# WS53 register map
File version: 0.1.0-experimental
Registers are 32-bit, read-write, no defined reset value unless marked. A register's access mark holds for its fields unless they carry their own. Offsets are from the block's base; [hi:lo] are bit positions; {n}, {i} and the like mark numbered series; 'fields as' and 'values as' point back to an identical list.

## SPI0
Base 0x52087000
0x00 ENABLE
  [0] START
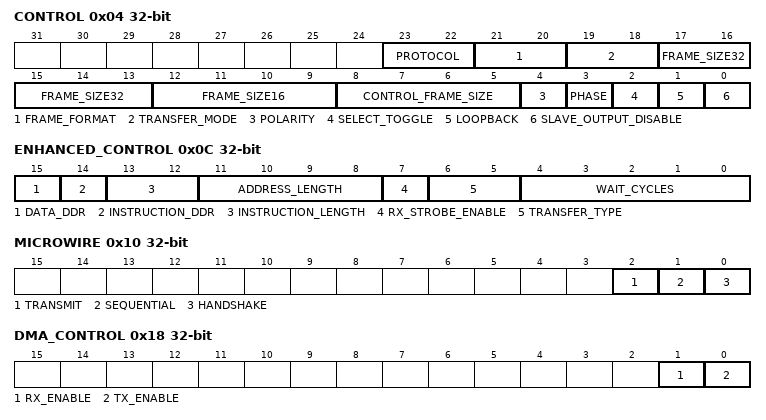
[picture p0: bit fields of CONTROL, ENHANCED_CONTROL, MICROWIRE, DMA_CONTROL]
0x04 CONTROL
  [23:22] PROTOCOL, [21:20] FRAME_FORMAT, [19:18] TRANSFER_MODE, [17:13] FRAME_SIZE32, [12:9] FRAME_SIZE16, [8:5] CONTROL_FRAME_SIZE, [4] POLARITY, [3] PHASE, [2] SELECT_TOGGLE, [1] LOOPBACK, [0] SLAVE_OUTPUT_DISABLE
0x08 FRAME_COUNT
  [15:0] VALUE
0x0C ENHANCED_CONTROL
  [15] DATA_DDR, [14] INSTRUCTION_DDR, [13:12] INSTRUCTION_LENGTH, [11:8] ADDRESS_LENGTH, [7] RX_STROBE_ENABLE, [6:5] TRANSFER_TYPE, [4:0] WAIT_CYCLES
0x10 MICROWIRE
  [2] TRANSMIT, [1] SEQUENTIAL, [0] HANDSHAKE
0x14 BAUD
  [15:0] VALUE — SDK header: even divider 2..65534, bit0 fixed zero; zero disables SCK. Setter truncates to 16 bits and does not round; silicon behavior unverified
0x18 DMA_CONTROL
  [1] RX_ENABLE, [0] TX_ENABLE
0x1C DMA_RX_LEVEL
  [31:0] VALUE
0x20 DMA_TX_LEVEL
  [31:0] VALUE
0x24 RX_SAMPLE_DELAY
  [7:0] VALUE
0x28 TX_DRIVE_EDGE
  [7:0] VALUE
{0x2C+4i} RX[{i}] (i=0..35) ro read-has-side-effects
  [31:0] DATA read-has-side-effects — Pop one received frame from the shared RX FIFO, regardless of window index
{0x2C+4i} TX[{i}] (i=0..35) wo (alternate view of RX[{i}])
  [31:0] DATA — Push one frame into the shared TX FIFO, regardless of window index
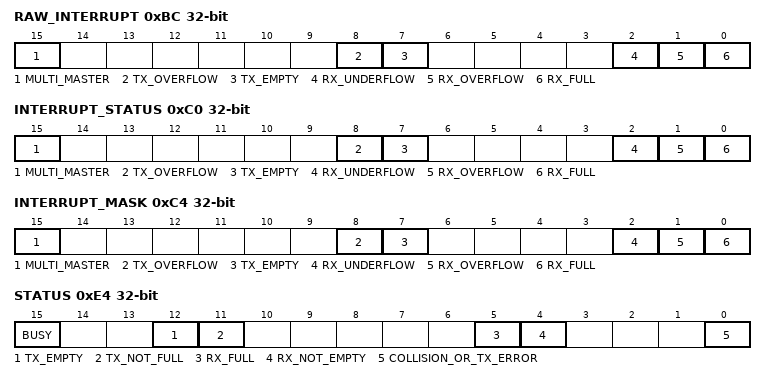
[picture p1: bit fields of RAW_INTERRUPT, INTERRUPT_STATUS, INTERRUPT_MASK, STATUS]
0xBC RAW_INTERRUPT ro
  [15] MULTI_MASTER, [8] TX_OVERFLOW, [7] TX_EMPTY, [2] RX_UNDERFLOW, [1] RX_OVERFLOW, [0] RX_FULL
0xC0 INTERRUPT_STATUS ro
  fields as RAW_INTERRUPT
0xC4 INTERRUPT_MASK
  fields as RAW_INTERRUPT
0xC8 SLAVE_ENABLE
  [15:0] VALUE
0xCC TX_THRESHOLD
  [31:0] VALUE
0xD0 TX_LEVEL ro
  [31:0] VALUE
0xD4 CLEAR_TX_OVERFLOW ro read-clears
  [0] CLEAR read-clears — Read acknowledges the corresponding interrupt; writes have no effect
0xD8 RX_THRESHOLD
  [31:0] VALUE
0xDC RX_LEVEL ro
  [31:0] VALUE
0xE0 CLEAR_RX_UNDERFLOW ro read-clears
  fields as CLEAR_TX_OVERFLOW
0xE4 STATUS ro read-modifies
  [15] BUSY
  [12] TX_EMPTY
  [11] TX_NOT_FULL
  [5] RX_FULL
  [4] RX_NOT_EMPTY
  [0] COLLISION_OR_TX_ERROR read-clears — SDK spi_wsr_data_t: master collision status clears on read. Retain the existing field name for API compatibility; the SDK documentation establishes master collision, not TX FIFO overflow. Relation to RAW_INTERRUPT acknowledgement is not established; do not use STATUS as an IRQ acknowledgement. SDK documentation, not silicon-qualified.
0xE8 CLEAR_MULTI_MASTER ro read-clears
  fields as CLEAR_TX_OVERFLOW
0xEC VERSION ro
  [31:0] VALUE
0xF4 CLEAR_RX_OVERFLOW ro read-clears
  fields as CLEAR_TX_OVERFLOW
0xF8 CLEAR_ALL ro read-clears
  fields as CLEAR_TX_OVERFLOW

## ADC
Base 0x5208A000
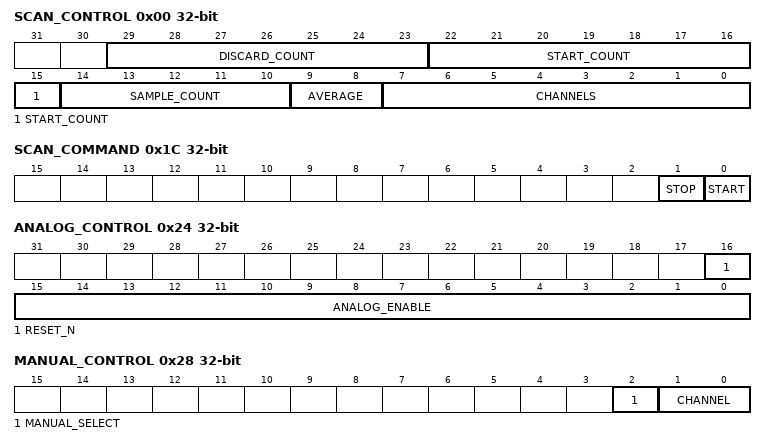
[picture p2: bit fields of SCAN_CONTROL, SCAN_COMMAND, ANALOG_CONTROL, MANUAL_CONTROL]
0x00 SCAN_CONTROL
  [29:23] DISCARD_COUNT
  [22:15] START_COUNT
  [14:10] SAMPLE_COUNT
  [9:8] AVERAGE
    0=ONE; 1=TWO; 2=FOUR; 3=EIGHT
  [7:0] CHANNELS
0x1C SCAN_COMMAND wo — Command view of lsadc_ctrl_8. SDK writes one to start/stop; self-clear and simultaneous command behavior unknown.
  [1] STOP, [0] START
0x24 ANALOG_CONTROL
  [16] RESET_N, [15:0] ANALOG_ENABLE
0x28 MANUAL_CONTROL
  [2] MANUAL_SELECT, [1:0] CHANNEL
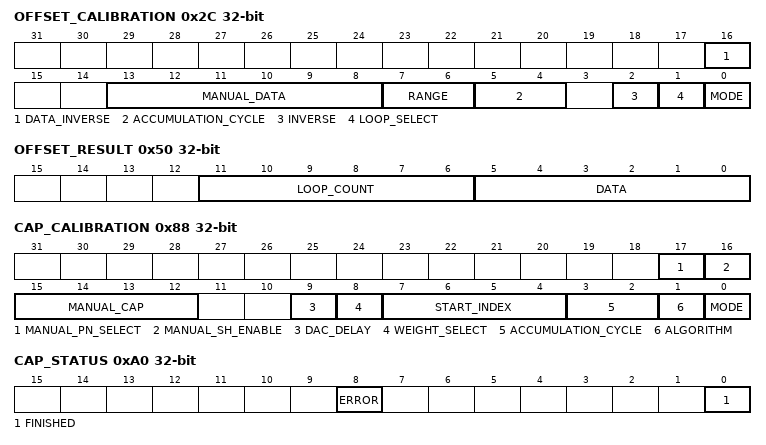
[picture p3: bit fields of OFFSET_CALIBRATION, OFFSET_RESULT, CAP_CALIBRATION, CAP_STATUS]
0x2C OFFSET_CALIBRATION
  [16] DATA_INVERSE, [13:8] MANUAL_DATA, [7:6] RANGE, [5:4] ACCUMULATION_CYCLE, [2] INVERSE, [1] LOOP_SELECT, [0] MODE
0x30 OFFSET_ENABLE
  [0] ENABLE
0x34 OFFSET_DATA_ENABLE
  [0] ENABLE
0x38 OFFSET_REFRESH wo — Command-only view: SDK explicitly writes 1 then 0; not a self-clearing or W1C declaration
  [0] PULSE
0x3C OFFSET_STATE_CLEAR wo — Command-only view: SDK explicitly writes 1 then 0 to clear finish state; readback unspecified
  [0] PULSE
0x44 OFFSET_STATUS ro
  [0] FINISHED
0x50 OFFSET_RESULT ro
  [11:6] LOOP_COUNT, [5:0] DATA
0x88 CAP_CALIBRATION
  [17] MANUAL_PN_SELECT, [16] MANUAL_SH_ENABLE, [15:12] MANUAL_CAP, [9] DAC_DELAY, [8] WEIGHT_SELECT, [7:4] START_INDEX, [3:2] ACCUMULATION_CYCLE, [1] ALGORITHM, [0] MODE
0x8C CAP_ENABLE
  [0] ENABLE
0x94 CAP_REFRESH wo — Command-only view: SDK explicitly writes 1 then 0
  [0] PULSE
0x98 CAP_FINISH_CLEAR wo — Command-only view: SDK explicitly writes 1 then 0 to clear finish state
  [0] PULSE
0x9C GAIN_STATE_CLEAR wo — Command-only view: SDK explicitly writes 1 then 0 to clear gain state
  [0] PULSE
0xA0 CAP_STATUS ro
  [8] ERROR, [0] FINISHED
{0xF4+4i} ANALOG_CONFIG[{i}] (i=0..2) wo — Opaque analog configuration written by the v155 SDK; individual field meanings are not documented
  [31:0] VALUE
